AUTOSAR XML (schema 4-3-0)
package /cdd_nfcic
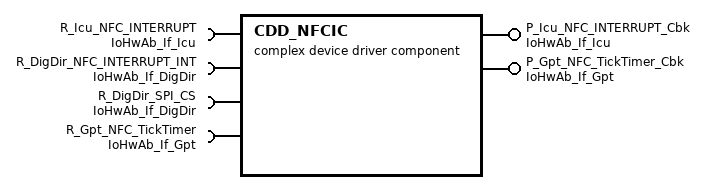
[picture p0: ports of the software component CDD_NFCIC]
  complex device driver sw component type CDD_NFCIC
    require port R_Icu_NFC_INTERRUPT: required-com-specs=[DisableNotification, EnableNotification, EnableEdgeDetection, DisableEdgeDetection], required-interface=IoHwAb_If_Icu
    provide port P_Icu_NFC_INTERRUPT_Cbk: server-com-spec{operation=Notification, queue-length=1}, provided-interface=IoHwAb_If_Icu
    require port R_DigDir_NFC_INTERRUPT_INT: client-com-spec=ReadDirect, required-interface=IoHwAb_If_DigDir
    require port R_DigDir_SPI_CS: client-com-spec=WriteDirect, required-interface=IoHwAb_If_DigDir
    require port R_Gpt_NFC_TickTimer: required-com-specs=[StartTimer, StopTimer, GetTimeElapsed, GetTimeRemaining, DisableNotification, EnableNotification], required-interface=IoHwAb_If_Gpt
    provide port P_Gpt_NFC_TickTimer_Cbk: server-com-spec{operation=Notification, queue-length=1}, provided-interface=IoHwAb_If_Gpt
    behavior InternalBehavior
      operation invoked event OIE_RE_IcuSignalEdgeDetection_NFC_INTERRUPT_P_Icu_NFC_INTERRUPT_Cbk_Notification: start-on-event=RE_IcuSignalEdgeDetection_NFC_INTERRUPT, operation=P_Icu_NFC_INTERRUPT_Cbk.Notification
      operation invoked event OIE_RE_NFC_TickTimer_Cbk_P_Gpt_NFC_TickTimer_Cbk_Notification: start-on-event=RE_NFC_TickTimer_Cbk, operation=P_Gpt_NFC_TickTimer_Cbk.Notification
      6 x runnable:
        RE_IcuSignalEdgeDetection_NFC_INTERRUPT: symbol=nfcic_interrup_Cbk
          5 x sync call:
            SSCP_RE_IcuSignalEdgeDetection_NFC_INTERRUPT_R_Icu_NFC_INTERRUPT_DisableEdgeDetection: operation=R_Icu_NFC_INTERRUPT.DisableEdgeDetection
            SSCP_RE_IcuSignalEdgeDetection_NFC_INTERRUPT_R_Icu_NFC_INTERRUPT_DisableNotification: operation=R_Icu_NFC_INTERRUPT.DisableNotification
            SSCP_RE_IcuSignalEdgeDetection_NFC_INTERRUPT_R_Icu_NFC_INTERRUPT_EnableEdgeDetection: operation=R_Icu_NFC_INTERRUPT.EnableEdgeDetection
            SSCP_RE_IcuSignalEdgeDetection_NFC_INTERRUPT_R_Icu_NFC_INTERRUPT_EnableNotification: operation=R_Icu_NFC_INTERRUPT.EnableNotification
            SSCP_RE_IcuSignalEdgeDetection_NFC_INTERRUPT_R_DigDir_NFC_INTERRUPT_INT_ReadDirect: operation=R_DigDir_NFC_INTERRUPT_INT.ReadDirect
        RE_NFCIC_Select: symbol=nfcic_Select
          sync call SSCP_RE_NFCIC_CS_Control_R_DigDir_SPI_CS_WriteDirect: operation=R_DigDir_SPI_CS.WriteDirect
        RE_NFCIC_Deselect: symbol=nfcic_Deselect
          sync call SSCP_RE_NFCIC_Deselect_R_DigDir_SPI_CS_WriteDirect: operation=R_DigDir_SPI_CS.WriteDirect, timeout=0.0
        RE_NFC_TickTimer_Start: symbol=nfc_ticktimer_start
          sync call SSCP_RE_NFC_TickTimer_Start_R_Gpt_NFC_TickTimer_GetTimeElapsed: operation=R_Gpt_NFC_TickTimer.GetTimeElapsed
          sync call SSCP_RE_NFC_TickTimer_Start_R_Gpt_NFC_TickTimer_StartTimer: operation=R_Gpt_NFC_TickTimer.StartTimer
        RE_NFC_TickTimer_Stop: symbol=nfc_ticktimer_stop
          sync call SSCP_RE_NFC_TickTimer_Stop_R_Gpt_NFC_TickTimer_StopTimer: operation=R_Gpt_NFC_TickTimer.StopTimer
        RE_NFC_TickTimer_Cbk: symbol=nfc_ticktimer_Cbk
          sync call SSCP_RE_NFC_TickTimer_Cbk_R_Gpt_NFC_TickTimer_DisableNotification: operation=R_Gpt_NFC_TickTimer.DisableNotification
          sync call SSCP_RE_NFC_TickTimer_Cbk_R_Gpt_NFC_TickTimer_EnableNotification: operation=R_Gpt_NFC_TickTimer.EnableNotification
